# MIK32 register map
Vendor: Mikron JSC; Series: MIK32; File version: 1.0
Registers are 32-bit, read-write, reset 0x0 unless marked. A register's access mark holds for its fields unless they carry their own. Offsets are from the block's base; [hi:lo] are bit positions; 'fields as' and 'values as' point back to an identical list; <NAME> marks a mode.

## USART_0 — Универсальный синхронный/асинхронный приёмопередатчик (УСАПП)
Base 0x00081400
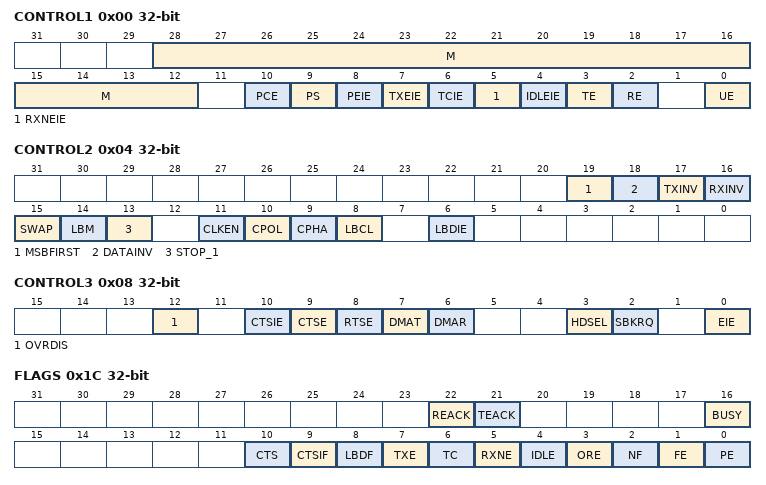
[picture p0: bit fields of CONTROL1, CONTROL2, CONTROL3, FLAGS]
0x00 CONTROL1 — Регистр управления 1
  [28:12] M — M1[28] и M0[12] управляют длиной кадра. Примечание: Эти биты могут быть изменены только при остановке работы (UE=0)
    0=8bits (8 бит данных); 1=9bits (9 бит данных); 0x10000=7bits (7 бит данных)
  [10] PCE — Контроль чётности. Примечание: Этот бит может быть изменён только при остановке работы (UE=0)
    0=Disable (Контроль чётности выключен); 1=Enable (Контроль чётности включен)
  [9] PS — Выбор способа формирования бита чётности. Примечание: Этот бит может быть изменён только при остановке работы (UE=0)
    0=Parity (Бит чётности); 1=Odd (Бит нечётности)
  [8] PEIE — Управление прерыванием при ошибке в принятом бите чётности
    0=Disable (Прерывание по ошибке в бите чётности выключено); 1=Enable (Прерывание по ошибке в бите чётности включено)
  [7] TXEIE — Управление прерыванием при передаче данных в момент записи данных в сдвиговый регистр
    0=Disable (Прерывание выключено); 1=Enable (Прерывание включено)
  [6] TCIE — Управление прерыванием при успешной передаче данных
    values as TXEIE
  [5] RXNEIE — Управление прерыванием при успешном приёме данных или перезаписи полученных данных
    values as TXEIE
  [4] IDLEIE — Управление прерыванием при отсутствии входных транзакций
    values as TXEIE
  [3] TE — Управление передатчиком
    0=Disable (Передатчик выключен); 1=Enable (Передатчик включен)
  [2] RE — Управление приёмником
    0=Disable (Приёмник выключен); 1=Enable (Приёмник включен)
  [0] UE — Ресет USART. Отменяет все текущие операции. Не очищает регистры конфигурации, но сбрасывает флаги
    0=Disable (USART выключен); 1=Enable (USART включён)
0x04 CONTROL2 — Регистр управления 2
  [19] MSBFIRST — Управление очередностью приёма и передачи данных. Этот бит не влияет на передачу и приём бита чётности. Этот бит может быть изменён только при остановке работы (UE=0)
    0=LSB (Начинать с 0 бита); 1=MSB (Начинать с 9, 8 или 7 в зависимости от настроек длины посылки.)
  [18] DATAINV — Управление полярностью принимаемых и передаваемых данных. Изменение полярности не влияет на бит чётности. Этот бит может быть изменён только при остановке работы (UE=0)
    0=Direct (Обычная полярность. 0 - низкий уровень, 1 - высокий уровень); 1=Inverted (Обратная полярность. 1 - низкий уровень, 0 - высокий уровень)
  [17] TXINV — Управление полярностью TX выхода. Регистр влияет не только на данные, но и на стоп биты, старт биты и тд. Этот бит может быть изменён только при остановке работы (UE=0)
    values as DATAINV
  [16] RXINV — Управление полярностью RX выхода. Регистр влияет не только на данные, но и на стоп биты, старт биты и тд. Этот бит может быть изменён только при остановке работы (UE=0)
    values as DATAINV
  [15] SWAP — Обмен функциями TX выхода и RX входа. Этот бит может быть изменён только при остановке работы (UE=0)
    0=Normal (Обычное функционирование); 1=Swap (Обмен функциями (TX = RX и RX = TX).)
  [14] LBM — Регистр режима обратной внутренней петли. Этот бит может быть изменён только при остановке работы (UE=0)
    0=Normal (Обычное функционирование); 1=Loopback (Сигналы TX и RTS подаются внутрь блока в обход входов RX и CTS. При этом TX = 1 и RTS = 1, входы RX и CTS не активны)
  [13] STOP_1 — Количество стоп битов для приёмника и передатчика. Этот бит может быть изменён только при остановке работы (UE=0)
    0=1bit (1 стоп бит); 1=2bits (2 стоп бита)
  [11] CLKEN — Управление синхронным режимом. Этот бит может быть изменён только при остановке работы (UE=0)
    0=Asynchronous (Синхронный режим выключен); 1=Synchronous (Синхронный режим включен)
  [10] CPOL — Управление полярностью выходного тактового сигнала CK. Этот бит может быть изменён только при остановке работы (UE=0)
    0=Логический «0» вне транзакции; 1=Логическая «1» вне транзакции
  [9] CPHA — Управление фазой выходного тактового сигнала CK. Этот бит может быть изменён только при остановке работы (UE=0)
    0=Первое изменение тактового сигнала – фронт; 1=Первое изменение тактового сигнала – спад (обратный фронт)
  [8] LBCL — Управление последним тактовым импульсом. Этот бит может быть изменён только при остановке работы (UE=0)
    0=Последний тактовый импульс отсутствует; 1=Последний тактовый импульс присутствует
  [6] LBDIE — Управление прерыванием при обнаружении break состояния на RX линии
    values as CONTROL1.TXEIE
0x08 CONTROL3 — Регистр управления 3
  [12] OVRDIS — Выбор реакции на переполнение. Этот бит может быть изменён только при остановке работы (UE=0)
    0=При переполнении взводится флаг ошибки (ORE), новые данные не записываются; 1=флаг переполнения не взводится, данные перезаписываются
  [10] CTSIE — Управление прерыванием при обнаружении изменения CTS
    values as CONTROL1.TXEIE
  [9] CTSE — Выбор реакции на входной сигнал CTS. Этот бит может быть изменён только при остановке работы (UE=0)
    0=Ignored (Сигнал игнорируется); 1=Control (Сигнал управляет передачей данных трансмиттером. Передача разрешена при (CTS = 0))
  [8] RTSE — Управление выходным сигналом RTS. Этот бит может быть изменён только при остановке работы (UE=0)
    0=Сигнал всегда в разрешающем состоянии (RTS = 0); 1=Сигнал находится в разрешающем состоянии (RTS = 0), только когда приёмник готов принять данные
  [7] DMAT — Управление работой сигнала dma_trq
    0=Disable (Сигнал выключен); 1=Enable (Сигнал включён)
  [6] DMAR — Управление работой сигнала dma_rrq
    0=Disable (Сигнал выключен); 1=Enable (Сигнал включён)
  [3] HDSEL — Выбор между полудуплексным и дуплексным режимами работы. В полудуплексном режиме RX не используется, все данные передаются и принимаются через TX. При наличии данных на передачу происходит отправка данных в остальное время приём. Этот бит может быть изменён только при остановке работы (UE=0)
    0=Duplex (Дуплексный режим работы); 1=Half_duplex (Полудуплексный режим работы)
  [2] SBKRQ — Переход передатчика в break состояние
    0=Normal (Обычный режим работы); 1=Break_tx (Состояние break на линии TX)
  [0] EIE — Управление прерыванием при обнаружении ошибок приёма данных (FE, ORE, NF)
    values as CONTROL1.TXEIE
0x0C DIVIDER — Регистр настройки делителя
  [15:0] BRR — Значение делителя входного тактового сигнала (clk_in). При BRR < 16 USART не активен Бодрейт рассчитывается по следующей формуле: BR = F/BRR, где BR - бодрейт, F - значение частоты входного тактового сигнала Этот бит может быть изменён только при остановке работы (UE=0)
0x1C FLAGS — Регистр прерываний
  [22] REACK ro — Флаг готовности приёмника к работе после снятия сброса (UE и RE)
    0=Unready (Ресет UE и RE активен); 1=Ready (Ресет UE и RE снят)
  [21] TEACK ro — Флаг готовности передатчика к работе после снятия сброса (UE и TE)
    0=Unready (Ресет UE и TE активен); 1=Ready (Ресет UE и TE снят)
  [16] BUSY ro — Флаг активности на линии RX
    0=Inactive (Нет активности на линии RX); 1=Active (Идёт передача данных или break состояние)
  [10] CTS ro — Флаг отображает текущее значение сигнала CTS
    0=CTS = 0; 1=CTS = 1
  [9] CTSIF write-1-clears — Флаг взводится при изменении значения сигнала CTS. Флаг сбрасывается записью «1»
    0=Состояние CTS не менялось с момента сброса флага; 1=Состояние CTS менялось с момента сброса флага
  [8] LBDF write-1-clears — Флаг обнаружения break состояния на линии RX. Флаг сбрасывается записью «1»
    0=Not_detected (Состояние break не обнаружено с момента сброса флага); 1=Detected (Состояние break обнаружено с момента сброса флага)
  [7] TXE write-1-clears — Флаг взводится при передаче данных в момент записи данных в сдвиговый регистр. Флаг сбрасывается записью данных в регистр TDR или записью «1»
    0=Данные не записывались в сдвиговый регистр с момента сброса флага; 1=Данные записывались в сдвиговый регистр
  [6] TC write-1-clears — Флаг взводится при передаче данных в момент отправки последнего стоп бита. Флаг сбрасывается записью «1»
    0=Данные не отправлялись с момента сброса флага; 1=Данные отправлялись с момента сброса флага
  [5] RXNE write-1-clears — Флаг взводится при записи принятых данных в регистр RDR из сдвигового регистра. Флаг сбрасывается записью «1» или чтением регистра RDR
    0=Данные не принимались после сброса флага; 1=Данные принимались после сброса флага
  [4] IDLE write-1-clears — Флаг взводится при отсутствии активности на линии RX в течении 8 битовых тактов при взведенном флаге RXNE. Флаг сбрасывается записью «1»
    0=Состояние idle не обнаружено после сброса флага; 1=Состояние idle обнаружено после сброса флага
  [3] ORE write-1-clears — Флаг взводится при попытке перезаписи RDR. Флаг сбрасывается записью «1»
    0=Попыток перезаписи не обнаружено с момента сброса флага; 1=Попытка перезаписи обнаружена с момента сброса флага
  [2] NF write-1-clears — Флаг обнаружения ложных переключений на линии RX. Флаг сбрасывается записью «1»
    0=Помех не обнаружено с момента сброса флага; 1=Помехи обнаружены с момента сброса флага
  [1] FE write-1-clears — Флаг взводится при обнаружении ошибок в стоп бите или битах. Флаг сбрасывается записью «1»
    0=Ошибок приёма не обнаружено с момента сброса флага; 1=Ошибка приёма обнаружена с момента сброса флага
  [0] PE write-1-clears — Флаг обнаружения ошибочного бита чётности. Флаг сбрасывается записью «1»
    0=Ошибок в битах чётности не обнаружено с момента сброса флага; 1=Ошибка в бите чётности обнаружена с момента сброса флага
0x24 RXDATA ro — Регистр принятых данных
  [8:0] RDR — Принятые данные
0x28 TXDATA — Регистр передаваемых данных
  [8:0] TDR — Передаваемые данные
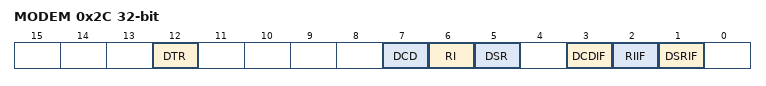
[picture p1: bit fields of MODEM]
0x2C MODEM — Регистр управления модемом
  [12] DTR — Регистр управления сигналом DTR
    0=Unready (Отсутствие сигнала готовности); 1=Ready (Готовность к приёму данных)
  [7] DCD ro — Регистр содержит текущее значение сигнала DCD
    0=Отсутствие несущей; 1=Обнаружение несущей
  [6] RI ro — Регистр содержит текущее значение сигнала RI
    0=Отсутствие звонка; 1=Звонок (вызов) на телефонной линии
  [5] DSR ro — Регистр содержит текущее значение сигнала DSR
    0=Unready (Источник данных не готов); 1=Ready (Источник данных готов)
  [3] DCDIF write-1-clears — Флаг взводится при изменении входного сигнала DCD. Флаг сбрасывается записью «1»
    0=Изменений сигнала не обнаружено с момента сброса флага; 1=Сигнал изменён с момента сброса флага
  [2] RIIF write-1-clears — Флаг взводится при изменении входного сигнала RI с «0» на «1». Флаг сбрасывается записью «1»
    0=Изменений сигнала с «0» на «1» не обнаружено с момента сброса флага; 1=Сигнал изменён с момента сброса флага
  [1] DSRIF write-1-clears — Флаг взводится при изменении входного сигнала DSR. Флаг сбрасывается записью «1»
    values as DCDIF
